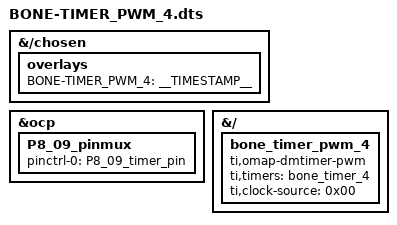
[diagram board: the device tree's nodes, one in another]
/*
 * Copyright (C) 2020 Deepak Khatri <deepaklorkhatri7@gmail.com>
 * See Cape Interface Spec page for more info on Bone Buses
 * https://elinux.org/Beagleboard:BeagleBone_cape_interface_spec
 *
 * Virtual cape for /sys/devices/platform/bone_timer_pwm_4/
 *
 * This program is free software; you can redistribute it and/or modify
 * it under the terms of the GNU General Public License version 2 as
 * published by the Free Software Foundation.
 */

/dts-v1/;
/plugin/;

/*
* Helper to show loaded overlays under: /proc/device-tree/chosen/overlays/
*/
&{/chosen} {
    overlays {
        BONE-TIMER_PWM_4 = __TIMESTAMP__;
    };
};

/*
 * Update the default pinmux of the pins.
 * See these files for the phandles (&P9_* & &P8_*)
 * BeagleBoard-DeviceTrees/v4.19.x-ti-overlays/src/arm/am335x-bone-common-univ.dtsi
 * BeagleBoard-DeviceTrees/v4.19.x-ti-overlays/src/arm/am572x-bone-common-univ.dtsi
 */
&ocp {
    P8_09_pinmux { pinctrl-0 = <&P8_09_timer_pin>; };    /* PWM A */
};

// See these files for the definition
// BeagleBoard-DeviceTrees/v4.19.x-ti-overlays/src/arm/bbai-bone-buses.dtsi
// BeagleBoard-DeviceTrees/v4.19.x-ti-overlays/src/arm/bbb-bone-buses.dtsi
&{/} {
	bone_timer_pwm_4 {
		compatible = "ti,omap-dmtimer-pwm";
		#pwm-cells = <3>;
		ti,timers = <&bone_timer_4>;
		//ti,prescaler = <0>;		/* 0 thru 7 */
		ti,clock-source = <0x00>;	/* timer_sys_ck */
		//ti,clock-source = <0x01>;	/* timer_32k_ck */
	};
};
